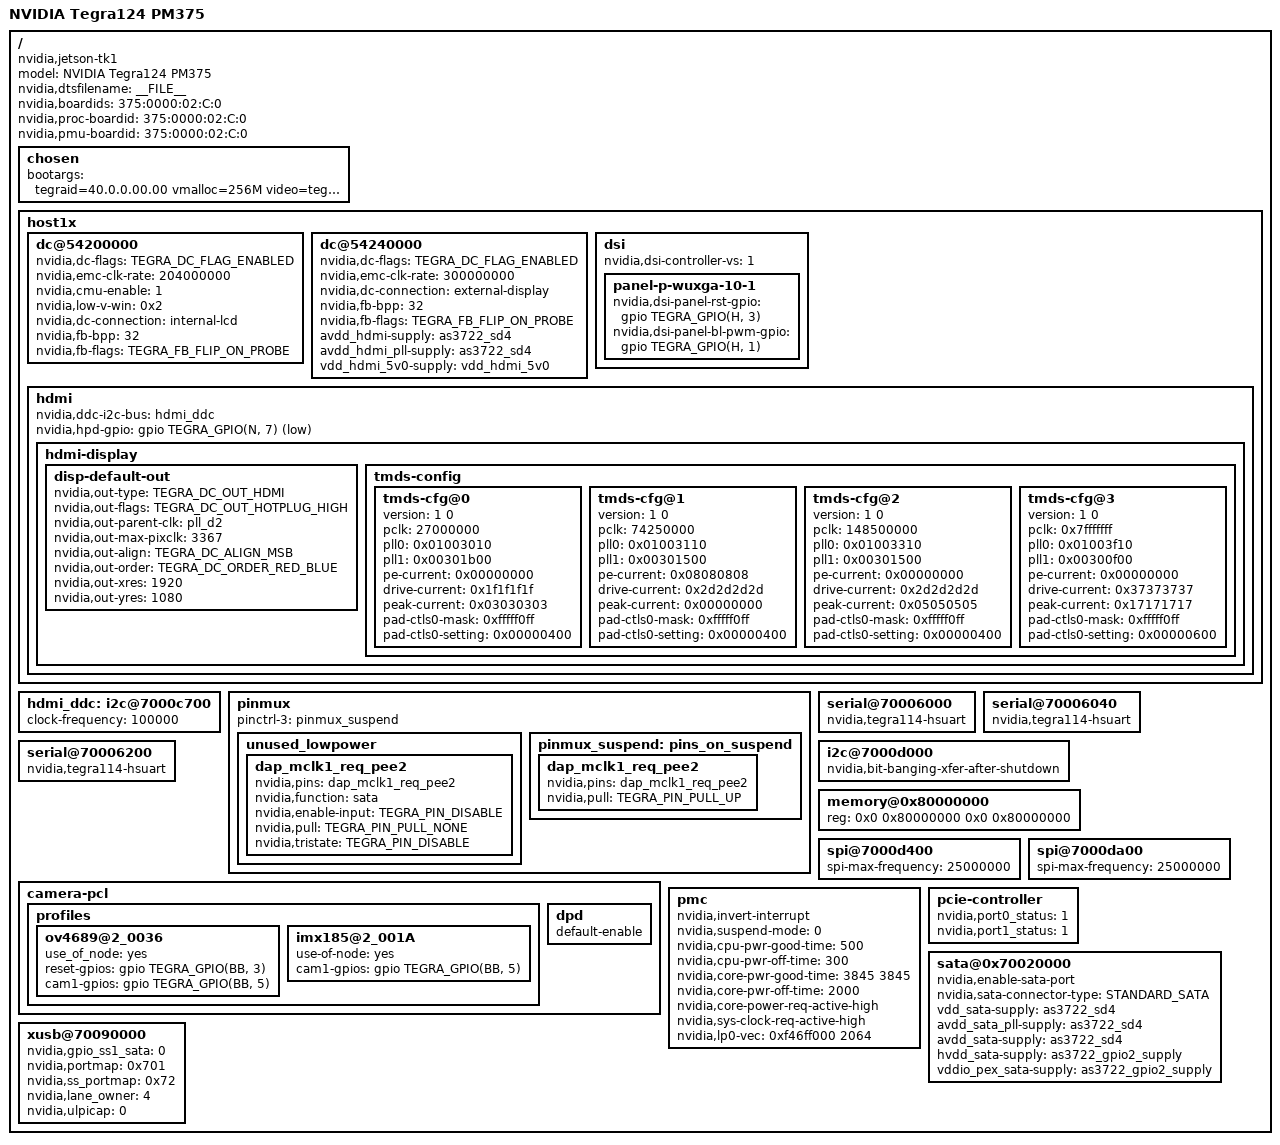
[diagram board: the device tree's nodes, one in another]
/dts-v1/;

#include "tegra124.dtsi"
#include "tegra124-platforms/tegra124-jetson_tk1-keys-pm375-0000-c00-00.dtsi"
#include "tegra124-platforms/tegra124-jetson_tk1-gpio-pm375-0000-c00-00.dtsi"
#include "tegra124-platforms/tegra124-jetson_tk1-pinmux-pm375-0000-c00-00.dtsi"
#include "tegra124-platforms/tegra124-jetson_tk1-pmic-pm375-0000-c00-00.dtsi"
#include "tegra124-platforms/tegra124-jetson_tk1-fixed-pm375-0000-c00-00.dtsi"
#include "tegra124-platforms/tegra124-pm359-camera-a00.dtsi"
#include "panel-p-wuxga-10-1.dtsi"


/ {
	model = "NVIDIA Tegra124 PM375";
	compatible = "nvidia,jetson-tk1", "nvidia,tegra124";
	nvidia,dtsfilename = __FILE__;
	#address-cells = <2>;
	#size-cells = <2>;

	/* 0x0177:0x0000:0x02:0x43:0x00 */
	nvidia,boardids = "375:0000:02:C:0";
	nvidia,dtsfilename = __FILE__;
	nvidia,proc-boardid = "375:0000:02:C:0";
	nvidia,pmu-boardid = "375:0000:02:C:0";

	chosen {
		bootargs = "tegraid=40.0.0.00.00 vmalloc=256M video=tegrafb console=ttyS0,115200n8 earlyprintk";
	};

	host1x {
		/* tegradc.0 */
		dc@54200000 {
			status = "okay";
			nvidia,dc-flags = <TEGRA_DC_FLAG_ENABLED>;
			nvidia,emc-clk-rate = <204000000>;
			nvidia,cmu-enable = <1>;
			nvidia,low-v-win = <0x2>;
			nvidia,dc-connection = "internal-lcd";
			nvidia,fb-bpp = <32>; /* bits per pixel */
			nvidia,fb-flags = <TEGRA_FB_FLIP_ON_PROBE>;
		};
		/* tegradc.1 */
		dc@54240000 {
			status = "okay";
			nvidia,dc-flags = <TEGRA_DC_FLAG_ENABLED>;
			nvidia,emc-clk-rate = <300000000>;
			nvidia,dc-connection = "external-display";
			nvidia,fb-bpp = <32>; /* bits per pixel */
			nvidia,fb-flags = <TEGRA_FB_FLIP_ON_PROBE>;
			avdd_hdmi-supply = <&as3722_sd4>;
			avdd_hdmi_pll-supply = <&as3722_sd4>;
			vdd_hdmi_5v0-supply = <&vdd_hdmi_5v0>;
		};
		dsi {
			nvidia,dsi-controller-vs = <1>;
			status = "okay";
			panel-p-wuxga-10-1 {
				nvidia,dsi-panel-rst-gpio = <&gpio TEGRA_GPIO(H, 3) 0>; /* PH3 */
				nvidia,dsi-panel-bl-pwm-gpio = <&gpio TEGRA_GPIO(H, 1) 0>; /* PH1 */
			};
		};
		hdmi {
			status = "okay";
			nvidia,ddc-i2c-bus = <&hdmi_ddc>;
			nvidia,hpd-gpio = <&gpio TEGRA_GPIO(N, 7) 1>; /* PN7 */
			hdmi-display {
				status = "okay";
				disp-default-out {
					nvidia,out-type = <TEGRA_DC_OUT_HDMI>;
					nvidia,out-flags = <TEGRA_DC_OUT_HOTPLUG_HIGH>;
					nvidia,out-parent-clk = "pll_d2";
					nvidia,out-max-pixclk = <3367>; /* KHZ2PICOS(297000) */
					nvidia,out-align = <TEGRA_DC_ALIGN_MSB>;
					nvidia,out-order = <TEGRA_DC_ORDER_RED_BLUE>;
					nvidia,out-xres = <1920>;
					nvidia,out-yres = <1080>;
				};
				tmds-config {
					tmds-cfg@0 {
						version = <1 0>;
						pclk = <27000000>;
						pll0 = <0x01003010>;
						pll1 = <0x00301b00>;
						pe-current = <0x00000000>;
						drive-current = <0x1f1f1f1f>;
						peak-current = <0x03030303>;
						pad-ctls0-mask = <0xfffff0ff>;
						pad-ctls0-setting = <0x00000400>;
					};
					tmds-cfg@1 {
						version = <1 0>;
						pclk = <74250000>;
						pll0 = <0x01003110>;
						pll1 = <0x00301500>;
						pe-current = <0x08080808>;
						drive-current = <0x2d2d2d2d>;
						peak-current = <0x00000000>;
						pad-ctls0-mask = <0xfffff0ff>;
						pad-ctls0-setting = <0x00000400>;
					};
					tmds-cfg@2 {
						version = <1 0>;
						pclk = <148500000>;
						pll0 = <0x01003310>;
						pll1 = <0x00301500>;
						pe-current = <0x00000000>;
						drive-current = <0x2d2d2d2d>;
						peak-current = <0x05050505>;
						pad-ctls0-mask = <0xfffff0ff>;
						pad-ctls0-setting = <0x00000400>;
					};
					tmds-cfg@3 {
						version = <1 0>;
						pclk = <0x7fffffff>;
						pll0 = <0x01003f10>;
						pll1 = <0x00300f00>;
						pe-current = <0x00000000>;
						drive-current = <0x37373737>;
						peak-current = <0x17171717>;
						pad-ctls0-mask = <0xfffff0ff>;
						pad-ctls0-setting = <0x00000600>;
					};
				};
			};
		};
	};

	hdmi_ddc: i2c@7000c700 {
		clock-frequency = <100000>;
	};

	pinmux {
		pinctrl-names = "default", "drive", "unused", "suspend";
		pinctrl-3 = <&pinmux_suspend>;

		/* Change the pin dap_mclk1_req to required configurations */
		unused_lowpower {
			dap_mclk1_req_pee2 {
			nvidia,pins = "dap_mclk1_req_pee2";
			nvidia,function = "sata";
			nvidia,enable-input = <TEGRA_PIN_DISABLE>;
			nvidia,pull = <TEGRA_PIN_PULL_NONE>;
			nvidia,tristate = <TEGRA_PIN_DISABLE>;
			};
		};

		/* On suspend, make dap_mclk1_req to pull up */
		pinmux_suspend: pins_on_suspend {
		dap_mclk1_req_pee2 {
			nvidia,pins = "dap_mclk1_req_pee2";
			nvidia,pull = <TEGRA_PIN_PULL_UP>;
			};
		};
	};

        serial@70006000 {
                compatible = "nvidia,tegra114-hsuart";
                status = "okay";
        };

        serial@70006040 {
                compatible = "nvidia,tegra114-hsuart";
                status = "okay";
        };

        serial@70006200 {
                compatible = "nvidia,tegra114-hsuart";
                status = "okay";
        };

	i2c@7000d000 {
		nvidia,bit-banging-xfer-after-shutdown;
	};

	memory@0x80000000 {
		device_type = "memory";
		reg = <0x0 0x80000000 0x0 0x80000000>;
	};

	camera-pcl {
		profiles {
			ov4689@2_0036 {
				use_of_node = "yes";
				reset-gpios = <&gpio TEGRA_GPIO(BB, 3) 0>;
				cam1-gpios = <&gpio TEGRA_GPIO(BB, 5) 0>;
			};
			imx185@2_001A {
				use-of-node = "yes";
				cam1-gpios = <&gpio TEGRA_GPIO(BB, 5) 0>;
			};
		};
		dpd {
			default-enable;
		};
	};

	spi@7000d400 {
		status = "okay";
		spi-max-frequency = <25000000>;
	};

	spi@7000da00 {
		status = "okay";
		spi-max-frequency = <25000000>;
	};

	pmc {
		status = "okay";
		nvidia,invert-interrupt;
		nvidia,suspend-mode = <0>;
		nvidia,cpu-pwr-good-time = <500>;
		nvidia,cpu-pwr-off-time = <300>;
		nvidia,core-pwr-good-time = <3845 3845>;
		nvidia,core-pwr-off-time = <2000>;
		nvidia,core-power-req-active-high;
		nvidia,sys-clock-req-active-high;
		nvidia,lp0-vec = <0xf46ff000 2064>;
	};

	pcie-controller {
		nvidia,port0_status = <1>;
		nvidia,port1_status = <1>;
		status = "okay";
	};

	sata@0x70020000 {
		nvidia,enable-sata-port;
		nvidia,sata-connector-type=<STANDARD_SATA>;
		vdd_sata-supply = <&as3722_sd4>;
		avdd_sata_pll-supply =<&as3722_sd4>;
		avdd_sata-supply = <&as3722_sd4>;
		hvdd_sata-supply = <&as3722_gpio2_supply>;
		vddio_pex_sata-supply = <&as3722_gpio2_supply>;
		status = "okay";
	};

	xusb@70090000 {
		/* nvidia,uses_external_pmic;
		nvidia,gpio_controls_muxed_ss_lanes; */
		nvidia,gpio_ss1_sata = <0>;
		nvidia,portmap = <0x701>; /* SSP0, USB2P0, USBP1, USBP2 */
		nvidia,ss_portmap = <0x72>; /* SSP0 on USB2P2 */
		nvidia,lane_owner = <4>; /* USB3P0 USB3P1 */
		nvidia,ulpicap = <0>; /* No ulpi support. can we remove */
		status = "okay";
	};
};
